# nrf9120_MLM1 register map
Vendor: Nordic Semiconductor; Series: nrf91; File version: 1
CPU: CM4 r0p1, little endian, MPU, FPU, 3 interrupt priority bits
Registers are 32-bit, read-write, reset 0x0 unless marked. A register's access mark holds for its fields unless they carry their own. Offsets are from the block's base; [hi:lo] are bit positions; lines under a group give offsets from that group; {n}, {i} and the like mark numbered series; 'fields as' and 'values as' point back to an identical list.

## TWIS0 — I2C compatible Two-Wire Slave Interface with EasyDMA 0
Base 0x40008000; alternate view of UARTE0
Same registers: TWIS1 0x40009000 (alternate view of UARTE1)
0x14 TASKS_STOP wo — Stop TWI transaction
0x1C TASKS_SUSPEND wo — Suspend TWI transaction
0x20 TASKS_RESUME wo — Resume TWI transaction
0x30 TASKS_PREPARERX wo — Prepare the TWI slave to respond to a write command
0x34 TASKS_PREPARETX wo — Prepare the TWI slave to respond to a read command
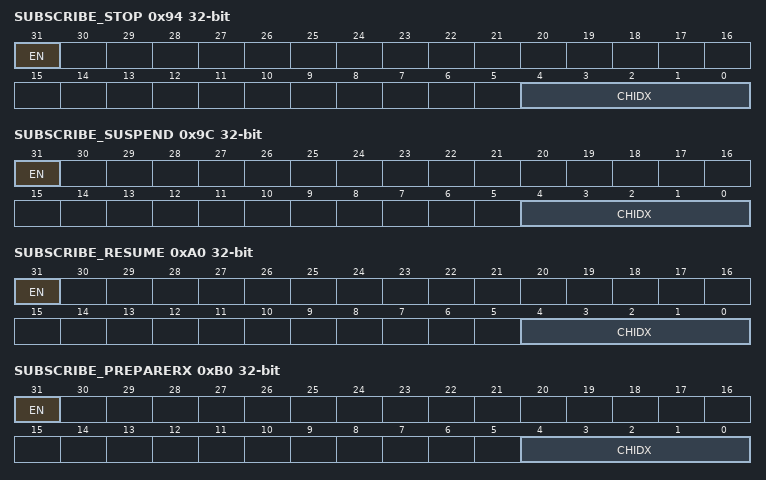
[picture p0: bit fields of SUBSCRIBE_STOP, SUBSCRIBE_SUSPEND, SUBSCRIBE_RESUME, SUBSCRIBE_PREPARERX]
0x94 SUBSCRIBE_STOP — Subscribe configuration for TASKS_STOP
  [31] EN
    0=Disabled (Disable subscription); 1=Enabled (Enable subscription)
  [4:0] CHIDX — Channel the TASKS_STOP will subscribe to.
0x9C SUBSCRIBE_SUSPEND — Subscribe configuration for TASKS_SUSPEND
  [31] EN
    values as SUBSCRIBE_STOP.EN
  [4:0] CHIDX — Channel the TASKS_SUSPEND will subscribe to.
0xA0 SUBSCRIBE_RESUME — Subscribe configuration for TASKS_RESUME
  [31] EN
    values as SUBSCRIBE_STOP.EN
  [4:0] CHIDX — Channel the TASKS_RESUME will subscribe to.
0xB0 SUBSCRIBE_PREPARERX — Subscribe configuration for TASKS_PREPARERX
  [31] EN
    values as SUBSCRIBE_STOP.EN
  [4:0] CHIDX — Channel the TASKS_PREPARERX will subscribe to.
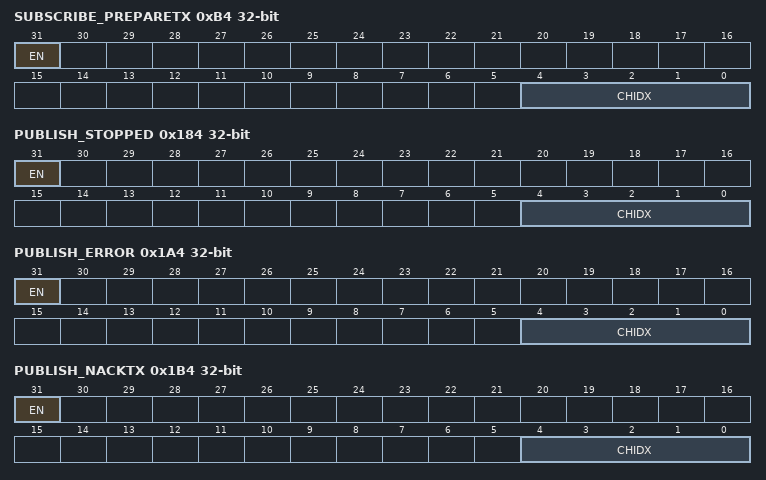
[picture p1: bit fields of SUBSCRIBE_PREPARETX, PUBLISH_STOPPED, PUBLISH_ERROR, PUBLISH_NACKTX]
0xB4 SUBSCRIBE_PREPARETX — Subscribe configuration for TASKS_PREPARETX
  [31] EN
    values as SUBSCRIBE_STOP.EN
  [4:0] CHIDX — Channel the TASKS_PREPARETX will subscribe to.
0x104 EVENTS_STOPPED — TWI stopped
0x124 EVENTS_ERROR — TWI error
0x134 EVENTS_NACKTX — NACK on TX
0x138 EVENTS_BB — TWI byte boundary, generated before each byte that is sent or received
0x14C EVENTS_RXSTARTED — Receive sequence started
0x150 EVENTS_TXSTARTED — Transmit sequence started
0x164 EVENTS_WRITE — Write command received
0x168 EVENTS_READ — Read command received
0x16C EVENTS_CSSTARTED — TWI started stretching the clock
0x170 EVENTS_CSSTOPPED — TWI stopped stretching the clock
0x184 PUBLISH_STOPPED — Publish configuration for EVENTS_STOPPED
  [31] EN
    0=Disabled (Disable publishing); 1=Enabled (Enable publishing)
  [4:0] CHIDX — Channel the EVENTS_STOPPED will subscribe to.
0x1A4 PUBLISH_ERROR — Publish configuration for EVENTS_ERROR
  [31] EN
    values as PUBLISH_STOPPED.EN
  [4:0] CHIDX — Channel the EVENTS_ERROR will subscribe to.
0x1B4 PUBLISH_NACKTX — Publish configuration for EVENTS_NACKTX
  [31] EN
    values as PUBLISH_STOPPED.EN
  [4:0] CHIDX — Channel the EVENTS_NACKTX will subscribe to.
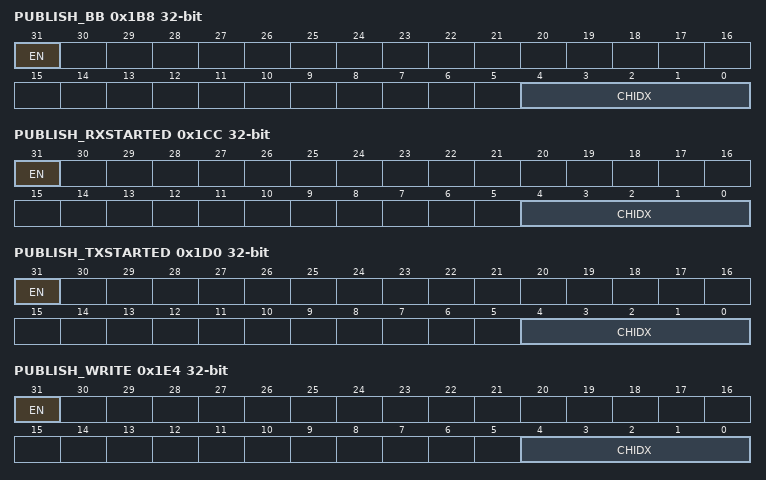
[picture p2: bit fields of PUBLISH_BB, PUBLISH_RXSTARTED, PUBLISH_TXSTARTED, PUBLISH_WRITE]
0x1B8 PUBLISH_BB — Publish configuration for EVENTS_BB
  [31] EN
    values as PUBLISH_STOPPED.EN
  [4:0] CHIDX — Channel the EVENTS_BB will subscribe to.
0x1CC PUBLISH_RXSTARTED — Publish configuration for EVENTS_RXSTARTED
  [31] EN
    values as PUBLISH_STOPPED.EN
  [4:0] CHIDX — Channel the EVENTS_RXSTARTED will subscribe to.
0x1D0 PUBLISH_TXSTARTED — Publish configuration for EVENTS_TXSTARTED
  [31] EN
    values as PUBLISH_STOPPED.EN
  [4:0] CHIDX — Channel the EVENTS_TXSTARTED will subscribe to.
0x1E4 PUBLISH_WRITE — Publish configuration for EVENTS_WRITE
  [31] EN
    values as PUBLISH_STOPPED.EN
  [4:0] CHIDX — Channel the EVENTS_WRITE will subscribe to.
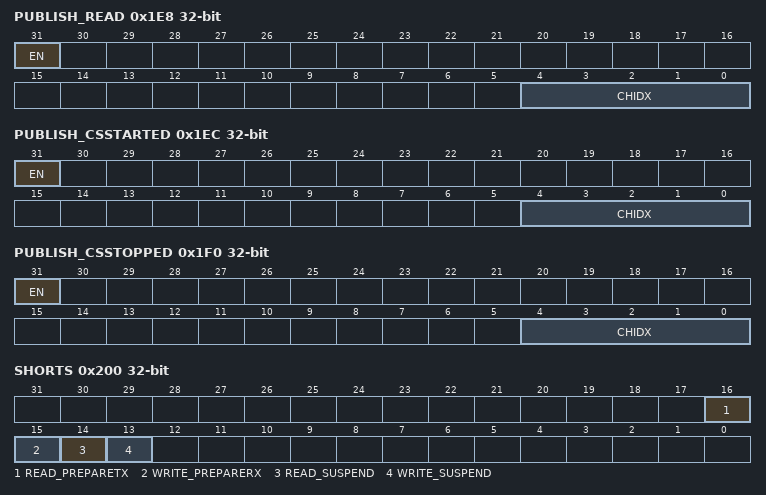
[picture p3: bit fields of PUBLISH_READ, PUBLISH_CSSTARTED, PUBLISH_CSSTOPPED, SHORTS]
0x1E8 PUBLISH_READ — Publish configuration for EVENTS_READ
  [31] EN
    values as PUBLISH_STOPPED.EN
  [4:0] CHIDX — Channel the EVENTS_READ will subscribe to.
0x1EC PUBLISH_CSSTARTED — Publish configuration for EVENTS_CSSTARTED
  [31] EN
    values as PUBLISH_STOPPED.EN
  [4:0] CHIDX — Channel the EVENTS_CSSTARTED will subscribe to.
0x1F0 PUBLISH_CSSTOPPED — Publish configuration for EVENTS_CSSTOPPED
  [31] EN
    values as PUBLISH_STOPPED.EN
  [4:0] CHIDX — Channel the EVENTS_CSSTOPPED will subscribe to.
0x200 SHORTS — Shortcut register
  [all] fields
    0=Disabled (Disable shortcut); 1=Enabled (Enable shortcut)
  [16] READ_PREPARETX — Shortcut between READ event and PREPARETX task
  [15] WRITE_PREPARERX — Shortcut between WRITE event and PREPARERX task
  [14] READ_SUSPEND — Shortcut between READ event and SUSPEND task
  [13] WRITE_SUSPEND — Shortcut between WRITE event and SUSPEND task
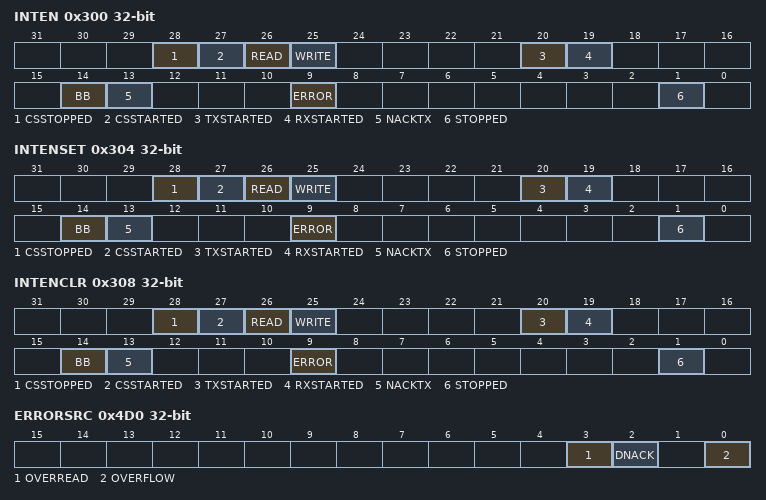
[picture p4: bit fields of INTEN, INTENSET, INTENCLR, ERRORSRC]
0x300 INTEN — Enable or disable interrupt
  [all] fields
    0=Disabled; 1=Enabled
  [28] CSSTOPPED — Enable or disable interrupt for CSSTOPPED event
  [27] CSSTARTED — Enable or disable interrupt for CSSTARTED event
  [26] READ — Enable or disable interrupt for READ event
  [25] WRITE — Enable or disable interrupt for WRITE event
  [20] TXSTARTED — Enable or disable interrupt for TXSTARTED event
  [19] RXSTARTED — Enable or disable interrupt for RXSTARTED event
  [14] BB — Enable or disable interrupt for BB event
  [13] NACKTX — Enable or disable interrupt for NACKTX event
  [9] ERROR — Enable or disable interrupt for ERROR event
  [1] STOPPED — Enable or disable interrupt for STOPPED event
0x304 INTENSET — Enable interrupt
  [all] fields
    on read: 0=Disabled (Read: Disabled); 1=Enabled (Read: Enabled) | on write: 1=Set (Enable)
  [28] CSSTOPPED — Write '1' to Enable interrupt for CSSTOPPED event
  [27] CSSTARTED — Write '1' to Enable interrupt for CSSTARTED event
  [26] READ — Write '1' to Enable interrupt for READ event
  [25] WRITE — Write '1' to Enable interrupt for WRITE event
  [20] TXSTARTED — Write '1' to Enable interrupt for TXSTARTED event
  [19] RXSTARTED — Write '1' to Enable interrupt for RXSTARTED event
  [14] BB — Write '1' to Enable interrupt for BB event
  [13] NACKTX — Write '1' to Enable interrupt for NACKTX event
  [9] ERROR — Write '1' to Enable interrupt for ERROR event
  [1] STOPPED — Write '1' to Enable interrupt for STOPPED event
0x308 INTENCLR — Disable interrupt
  [all] fields
    on read: 0=Disabled (Read: Disabled); 1=Enabled (Read: Enabled) | on write: 1=Clear (Disable)
  [28] CSSTOPPED — Write '1' to Disable interrupt for CSSTOPPED event
  [27] CSSTARTED — Write '1' to Disable interrupt for CSSTARTED event
  [26] READ — Write '1' to Disable interrupt for READ event
  [25] WRITE — Write '1' to Disable interrupt for WRITE event
  [20] TXSTARTED — Write '1' to Disable interrupt for TXSTARTED event
  [19] RXSTARTED — Write '1' to Disable interrupt for RXSTARTED event
  [14] BB — Write '1' to Disable interrupt for BB event
  [13] NACKTX — Write '1' to Disable interrupt for NACKTX event
  [9] ERROR — Write '1' to Disable interrupt for ERROR event
  [1] STOPPED — Write '1' to Disable interrupt for STOPPED event
0x4D0 ERRORSRC write-1-clears — Error source
  [3] OVERREAD — TX buffer over-read detected, and prevented
    0=NotDetected (Error did not occur); 1=Detected (Error occurred)
  [2] DNACK — NACK sent after receiving a data byte
    0=NotReceived (Error did not occur); 1=Received (Error occurred)
  [0] OVERFLOW — RX buffer overflow detected, and prevented
    values as OVERREAD
0x4D4 MATCH ro — Status register indicating which address had a match
  [0] MATCH — Which of the addresses in {ADDRESS} matched the incoming address
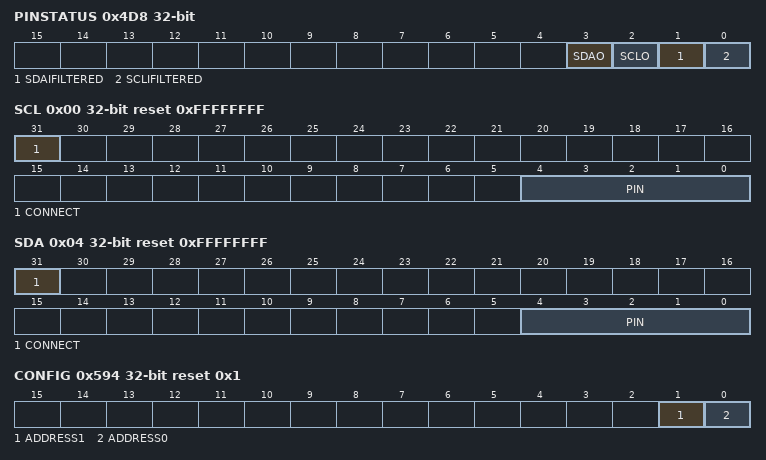
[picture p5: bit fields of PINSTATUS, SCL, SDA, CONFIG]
0x4D8 PINSTATUS ro — Returns state of signals reflecting the SDA and SCL line status. All fields will return a '0' if DEBUGENABLE is not Enabled.
  [3] SDAO — State of SDAO register in dataHandler
  [2] SCLO — State of SCLO register in dataHandler
  [1] SDAIFILTERED — State of SDA line, signal taken after the filer but without synchronizing to the 16 MHz clock
  [0] SCLIFILTERED — State of SCL line, signal taken after the filer but without synchronizing to the 16 MHz clock
0x500 ENABLE — Enable TWIS
  [3:0] ENABLE — Enable or disable TWIS
    0=Disabled (Disable TWIS); 9=Enabled (Enable TWIS)
0x508 PSEL group — Unspecified
  0x00 SCL reset 0xFFFFFFFF — Pin select for SCL signal
    [31] CONNECT — Connection
      1=Disconnected; 0=Connected
    [4:0] PIN — Pin number
  0x04 SDA reset 0xFFFFFFFF — Pin select for SDA signal
    fields as PSEL.SCL
0x534 RXD group — RXD EasyDMA channel
  0x00 PTR — RXD Data pointer
  0x04 MAXCNT — Maximum number of bytes in RXD buffer
    [7:0] MAXCNT
  0x08 AMOUNT ro — Number of bytes transferred in the last RXD transaction
    [7:0] AMOUNT
0x544 TXD group — TXD EasyDMA channel
  0x00 PTR — TXD Data pointer
  0x04 MAXCNT — Maximum number of bytes in TXD buffer
    [7:0] MAXCNT
  0x08 AMOUNT ro — Number of bytes transferred in the last TXD transaction
    [7:0] AMOUNT
{0x588+4i} ADDRESS[{i}] (i=0..1) — Description collection[0]: TWI slave address 0
  [6:0] ADDRESS — TWI slave address
0x594 CONFIG reset 0x1 — Configuration register for the address match mechanism
  [1] ADDRESS1 — Enable or disable address matching on ADDRESS[1]
    0=Disabled; 1=Enabled
  [0] ADDRESS0 — Enable or disable address matching on ADDRESS[0]
    0=Disabled; 1=Enabled
0x5A0 INPUTMODE
  [1:0] INPUTMODE
    0=Analog filtering; 1=Digital filtering; 2=Disabled (No filtering)
0x5A4 DEBUGENABLE — Enable TWIS debug features (PINSTATUS register)
  [0] ENABLE — Enable or disable TWIS
    0=Disabled (Disable TWIS); 1=Enabled (Enable TWIS debug features)
0x5C0 ORC — Over-read character. Character sent out in case of an over-read of the transmit buffer.
  [7:0] ORC
0xFFC POWER reset 0x1 — Peripheral power control
  [0] POWER — Peripheral power control. The peripheral and its registers will be reset to its initial state by switching the peripheral off and then back on again.
    0=Disabled (Peripheral is powered off); 1=Enabled (Peripheral is powered on)
